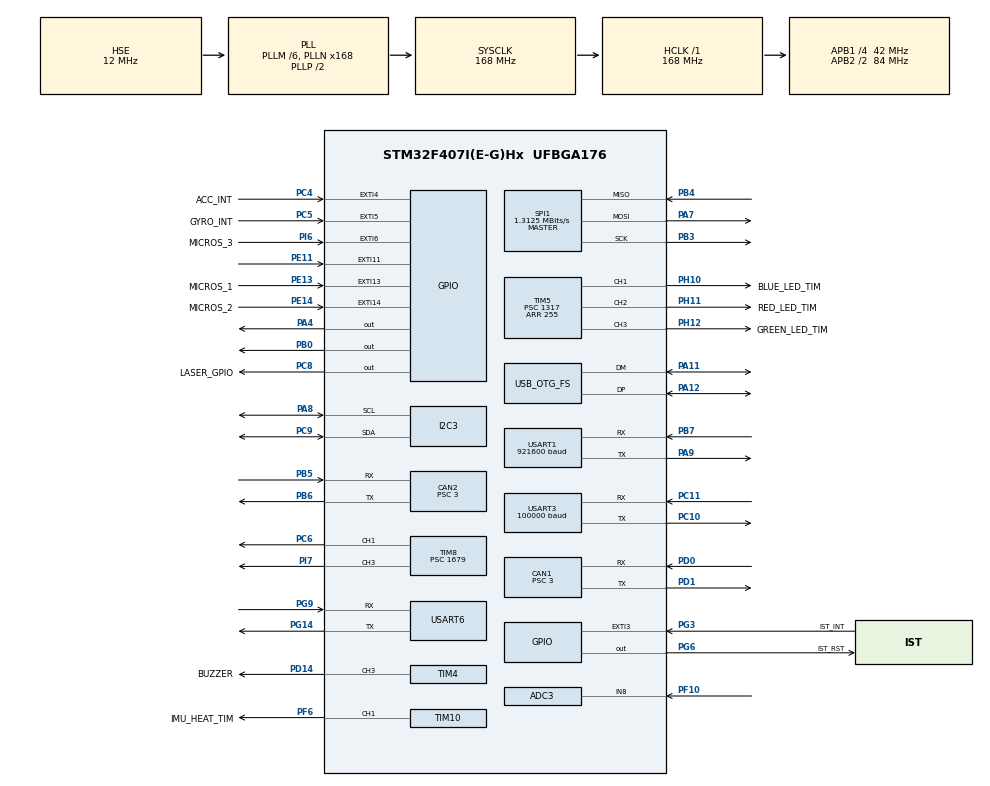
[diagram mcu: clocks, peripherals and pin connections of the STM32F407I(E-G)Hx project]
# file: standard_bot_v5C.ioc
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ADC3.Channel-0\#ChannelRegularConversion=ADC_CHANNEL_8
ADC3.NbrOfConversionFlag=1
ADC3.Rank-0\#ChannelRegularConversion=1
ADC3.SamplingTime-0\#ChannelRegularConversion=ADC_SAMPLETIME_3CYCLES
CAN1.ABOM=ENABLE
CAN1.BS1=CAN_BS1_10TQ
CAN1.BS2=CAN_BS2_3TQ
CAN1.CalculateBaudRate=1000000
CAN1.CalculateTimeBit=1000
CAN1.CalculateTimeQuantum=71.42857142857143
CAN1.NART=ENABLE
CAN1.Prescaler=3
CAN2.ABOM=ENABLE
CAN2.BS1=CAN_BS1_10TQ
CAN2.BS2=CAN_BS2_3TQ
CAN2.CalculateBaudRate=1000000
CAN2.CalculateTimeBit=1000
CAN2.CalculateTimeQuantum=71.42857142857143
CAN2.NART=ENABLE
CAN2.Prescaler=3
Dma.I2C3_RX.3.Direction=DMA_PERIPH_TO_MEMORY
Dma.I2C3_RX.3.FIFOMode=DMA_FIFOMODE_DISABLE
Dma.I2C3_RX.3.Instance=DMA1_Stream2
Dma.I2C3_RX.3.MemDataAlignment=DMA_MDATAALIGN_BYTE
Dma.I2C3_RX.3.MemInc=DMA_MINC_ENABLE
Dma.I2C3_RX.3.Mode=DMA_NORMAL
Dma.I2C3_RX.3.PeriphDataAlignment=DMA_PDATAALIGN_BYTE
Dma.I2C3_RX.3.PeriphInc=DMA_PINC_DISABLE
Dma.I2C3_RX.3.Priority=DMA_PRIORITY_LOW
Dma.I2C3_TX.4.Direction=DMA_MEMORY_TO_PERIPH
Dma.I2C3_TX.4.FIFOMode=DMA_FIFOMODE_DISABLE
Dma.I2C3_TX.4.Instance=DMA1_Stream4
Dma.I2C3_TX.4.MemDataAlignment=DMA_MDATAALIGN_BYTE
Dma.I2C3_TX.4.MemInc=DMA_MINC_ENABLE
Dma.I2C3_TX.4.Mode=DMA_NORMAL
Dma.I2C3_TX.4.PeriphDataAlignment=DMA_PDATAALIGN_BYTE
Dma.I2C3_TX.4.PeriphInc=DMA_PINC_DISABLE
Dma.I2C3_TX.4.Priority=DMA_PRIORITY_LOW
Dma.Request0=USART6_RX
Dma.Request1=USART3_RX
Dma.Request2=USART1_RX
Dma.Request3=I2C3_RX
Dma.Request4=I2C3_TX
Dma.Request5=SPI1_RX
Dma.Request6=SPI1_TX
Dma.Request7=USART6_TX
Dma.SPI1_RX.5.Direction=DMA_PERIPH_TO_MEMORY
Dma.SPI1_RX.5.FIFOMode=DMA_FIFOMODE_DISABLE
Dma.SPI1_RX.5.Instance=DMA2_Stream0
Dma.SPI1_RX.5.MemDataAlignment=DMA_MDATAALIGN_BYTE
Dma.SPI1_RX.5.MemInc=DMA_MINC_ENABLE
Dma.SPI1_RX.5.Mode=DMA_NORMAL
Dma.SPI1_RX.5.PeriphDataAlignment=DMA_PDATAALIGN_BYTE
Dma.SPI1_RX.5.PeriphInc=DMA_PINC_DISABLE
Dma.SPI1_RX.5.Priority=DMA_PRIORITY_LOW
Dma.SPI1_TX.6.Direction=DMA_MEMORY_TO_PERIPH
Dma.SPI1_TX.6.FIFOMode=DMA_FIFOMODE_DISABLE
Dma.SPI1_TX.6.Instance=DMA2_Stream3
Dma.SPI1_TX.6.MemDataAlignment=DMA_MDATAALIGN_BYTE
Dma.SPI1_TX.6.MemInc=DMA_MINC_ENABLE
Dma.SPI1_TX.6.Mode=DMA_NORMAL
Dma.SPI1_TX.6.PeriphDataAlignment=DMA_PDATAALIGN_BYTE
Dma.SPI1_TX.6.PeriphInc=DMA_PINC_DISABLE
Dma.SPI1_TX.6.Priority=DMA_PRIORITY_LOW
Dma.USART1_RX.2.Direction=DMA_PERIPH_TO_MEMORY
Dma.USART1_RX.2.FIFOMode=DMA_FIFOMODE_DISABLE
Dma.USART1_RX.2.Instance=DMA2_Stream5
Dma.USART1_RX.2.MemDataAlignment=DMA_MDATAALIGN_BYTE
Dma.USART1_RX.2.MemInc=DMA_MINC_ENABLE
Dma.USART1_RX.2.Mode=DMA_CIRCULAR
Dma.USART1_RX.2.PeriphDataAlignment=DMA_PDATAALIGN_BYTE
Dma.USART1_RX.2.PeriphInc=DMA_PINC_DISABLE
Dma.USART1_RX.2.Priority=DMA_PRIORITY_LOW
Dma.USART3_RX.1.Direction=DMA_PERIPH_TO_MEMORY
Dma.USART3_RX.1.FIFOMode=DMA_FIFOMODE_DISABLE
Dma.USART3_RX.1.Instance=DMA1_Stream1
Dma.USART3_RX.1.MemDataAlignment=DMA_MDATAALIGN_BYTE
Dma.USART3_RX.1.MemInc=DMA_MINC_ENABLE
Dma.USART3_RX.1.Mode=DMA_CIRCULAR
Dma.USART3_RX.1.PeriphDataAlignment=DMA_PDATAALIGN_BYTE
Dma.USART3_RX.1.PeriphInc=DMA_PINC_DISABLE
Dma.USART3_RX.1.Priority=DMA_PRIORITY_LOW
Dma.USART6_RX.0.Direction=DMA_PERIPH_TO_MEMORY
Dma.USART6_RX.0.FIFOMode=DMA_FIFOMODE_DISABLE
Dma.USART6_RX.0.Instance=DMA2_Stream1
Dma.USART6_RX.0.MemDataAlignment=DMA_MDATAALIGN_BYTE
Dma.USART6_RX.0.MemInc=DMA_MINC_ENABLE
Dma.USART6_RX.0.Mode=DMA_CIRCULAR
Dma.USART6_RX.0.PeriphDataAlignment=DMA_PDATAALIGN_BYTE
Dma.USART6_RX.0.PeriphInc=DMA_PINC_DISABLE
Dma.USART6_RX.0.Priority=DMA_PRIORITY_LOW
Dma.USART6_TX.7.Direction=DMA_MEMORY_TO_PERIPH
Dma.USART6_TX.7.FIFOMode=DMA_FIFOMODE_DISABLE
Dma.USART6_TX.7.Instance=DMA2_Stream6
Dma.USART6_TX.7.MemDataAlignment=DMA_MDATAALIGN_BYTE
Dma.USART6_TX.7.MemInc=DMA_MINC_ENABLE
Dma.USART6_TX.7.Mode=DMA_NORMAL
Dma.USART6_TX.7.PeriphDataAlignment=DMA_PDATAALIGN_BYTE
Dma.USART6_TX.7.PeriphInc=DMA_PINC_DISABLE
Dma.USART6_TX.7.Priority=DMA_PRIORITY_LOW
FREERTOS.INCLUDE_xEventGroupSetBitFromISR=1
FREERTOS.Tasks01=defaultTask,24,256,StartDefaultTask,Default,NULL,Dynamic,NULL,NULL
FREERTOS.configCHECK_FOR_STACK_OVERFLOW=1
FREERTOS.configENABLE_FPU=1
FREERTOS.configGENERATE_RUN_TIME_STATS=1
FREERTOS.configMINIMAL_STACK_SIZE=256
FREERTOS.configTOTAL_HEAP_SIZE=45000
FREERTOS.configUSE_NEWLIB_REENTRANT=1
FREERTOS.configUSE_STATS_FORMATTING_FUNCTIONS=1
I2C3.I2C_Mode=I2C_Fast
Mcu.Family=STM32F4
Mcu.Name=STM32F407I(E-G)Hx
Mcu.Package=UFBGA176
Mcu.UserConstants=FREERTOS_ENABLED,1
NVIC.CAN1_RX0_IRQn=true\:5\:0\:false\:false\:true\:true\:true\:true\:true
NVIC.CAN1_RX1_IRQn=true\:5\:0\:false\:false\:true\:true\:true\:true\:true
NVIC.CAN2_RX0_IRQn=true\:5\:0\:false\:false\:true\:true\:true\:true\:true
NVIC.CAN2_RX1_IRQn=true\:5\:0\:false\:false\:true\:true\:true\:true\:true
NVIC.DMA1_Stream1_IRQn=true\:5\:0\:false\:false\:true\:true\:false\:true\:true
NVIC.DMA1_Stream2_IRQn=true\:5\:0\:false\:false\:true\:true\:false\:true\:true
NVIC.DMA1_Stream4_IRQn=true\:5\:0\:false\:false\:true\:true\:false\:true\:true
NVIC.DMA2_Stream0_IRQn=true\:5\:0\:false\:false\:true\:true\:false\:true\:true
NVIC.DMA2_Stream1_IRQn=true\:5\:0\:false\:false\:true\:true\:false\:true\:true
NVIC.DMA2_Stream3_IRQn=true\:5\:0\:false\:false\:true\:true\:false\:true\:true
NVIC.DMA2_Stream5_IRQn=true\:5\:0\:false\:false\:true\:false\:false\:true\:true
NVIC.DMA2_Stream6_IRQn=true\:5\:0\:false\:false\:true\:true\:false\:true\:true
NVIC.EXTI15_10_IRQn=true\:5\:0\:false\:false\:true\:true\:true\:true\:true
NVIC.EXTI3_IRQn=true\:5\:0\:false\:false\:true\:true\:true\:true\:true
NVIC.EXTI4_IRQn=true\:5\:0\:false\:false\:true\:true\:true\:true\:true
NVIC.EXTI9_5_IRQn=true\:5\:0\:false\:false\:true\:true\:true\:true\:true
NVIC.I2C3_ER_IRQn=true\:5\:0\:false\:false\:true\:true\:true\:true\:true
NVIC.OTG_FS_IRQn=true\:5\:0\:false\:false\:true\:true\:false\:true\:true
NVIC.PriorityGroup=NVIC_PRIORITYGROUP_4
NVIC.TIM3_IRQn=true\:5\:0\:false\:false\:true\:true\:true\:true\:true
NVIC.TIM6_DAC_IRQn=true\:15\:0\:true\:false\:true\:false\:false\:true\:true
NVIC.TimeBase=TIM6_DAC_IRQn
NVIC.TimeBaseIP=TIM6
NVIC.USART1_IRQn=true\:5\:0\:false\:false\:true\:true\:true\:true\:true
NVIC.USART3_IRQn=true\:5\:0\:false\:false\:true\:true\:true\:true\:true
NVIC.USART6_IRQn=true\:5\:0\:false\:false\:true\:true\:true\:true\:true
PA11.Mode=Device_Only
PA11.Signal=USB_OTG_FS_DM
PA12.Mode=Device_Only
PA12.Signal=USB_OTG_FS_DP
PA13.Mode=Serial_Wire
PA13.Signal=SYS_JTMS-SWDIO
PA14.Mode=Serial_Wire
PA14.Signal=SYS_JTCK-SWCLK
PA4.PinState=GPIO_PIN_SET
PA4.Signal=GPIO_Output
PA7.Mode=Full_Duplex_Master
PA7.Signal=SPI1_MOSI
PA8.GPIO_Pu=GPIO_PULLUP
PA8.Mode=I2C
PA8.Signal=I2C3_SCL
PA9.Mode=Asynchronous
PA9.Signal=USART1_TX
PB0.PinState=GPIO_PIN_SET
PB0.Signal=GPIO_Output
PB3.Mode=Full_Duplex_Master
PB3.Signal=SPI1_SCK
PB4.Mode=Full_Duplex_Master
PB4.Signal=SPI1_MISO
PB5.Mode=CAN_Activate
PB5.Signal=CAN2_RX
PB6.Mode=CAN_Activate
PB6.Signal=CAN2_TX
PB7.GPIO_PuPd=GPIO_NOPULL
PB7.Mode=Asynchronous
PB7.Signal=USART1_RX
PC10.Mode=Asynchronous
PC10.Signal=USART3_TX
PC11.Mode=Asynchronous
PC11.Signal=USART3_RX
PC4.GPIO_Label=ACC_INT
PC4.GPIO_ModeDefaultEXTI=GPIO_MODE_IT_FALLING
PC4.GPIO_PuPd=GPIO_PULLUP
PC4.Signal=GPXTI4
PC5.GPIO_Label=GYRO_INT
PC5.GPIO_ModeDefaultEXTI=GPIO_MODE_IT_FALLING
PC5.GPIO_PuPd=GPIO_PULLUP
PC5.Signal=GPXTI5
PC6.Signal=S_TIM8_CH1
PC8.GPIO_Label=LASER_GPIO
PC8.PinState=GPIO_PIN_RESET
PC8.Signal=GPIO_Output
PC9.GPIO_Pu=GPIO_PULLUP
PC9.Mode=I2C
PC9.Signal=I2C3_SDA
PD0.Mode=CAN_Activate
PD0.Signal=CAN1_RX
PD1.Mode=CAN_Activate
PD1.Signal=CAN1_TX
PD14.GPIO_Label=BUZZER
PD14.Signal=S_TIM4_CH3
PE11.GPIO_ModeDefaultEXTI=GPIO_MODE_IT_RISING_FALLING
PE11.GPIO_PuPd=GPIO_PULLDOWN
PE11.Signal=GPXTI11
PE13.GPIO_Label=MICROS_1
PE13.GPIO_ModeDefaultEXTI=GPIO_MODE_IT_RISING_FALLING
PE13.GPIO_PuPd=GPIO_PULLUP
PE13.Signal=GPXTI13
PE14.GPIO_Label=MICROS_2
PE14.GPIO_PuPd=GPIO_PULLUP
PE14.Signal=GPXTI14
PF10.Mode=IN8
PF10.Signal=ADC3_IN8
PF6.GPIO_Label=IMU_HEAT_TIM
PF6.Signal=S_TIM10_CH1
PG14.Mode=Asynchronous
PG14.Signal=USART6_TX
PG3.GPIO_Label=IST_INT
PG3.GPIO_ModeDefaultEXTI=GPIO_MODE_IT_FALLING
PG3.GPIO_PuPd=GPIO_PULLUP
PG3.Signal=GPXTI3
PG6.GPIO_Label=IST_RST
PG6.Signal=GPIO_Output
PG9.Mode=Asynchronous
PG9.Signal=USART6_RX
PH0-OSC_IN.Mode=HSE-External-Oscillator
PH0-OSC_IN.Signal=RCC_OSC_IN
PH1-OSC_OUT.Mode=HSE-External-Oscillator
PH1-OSC_OUT.Signal=RCC_OSC_OUT
PH10.GPIO_Label=BLUE_LED_TIM
PH10.Signal=S_TIM5_CH1
PH11.GPIO_Label=RED_LED_TIM
PH11.Signal=S_TIM5_CH2
PH12.GPIO_Label=GREEN_LED_TIM
PH12.Signal=S_TIM5_CH3
PI6.GPIO_Label=MICROS_3
PI6.GPIO_PuPd=GPIO_PULLUP
PI6.Signal=GPXTI6
PI7.Signal=S_TIM8_CH3
ProjectManager.HeapSize=0x4000
ProjectManager.StackSize=0x9000
ProjectManager.TargetToolchain=STM32CubeIDE
RCC.48MHZClocksFreq_Value=48000000
RCC.AHBFreq_Value=168000000
RCC.APB1CLKDivider=RCC_HCLK_DIV4
RCC.APB1Freq_Value=42000000
RCC.APB1TimFreq_Value=84000000
RCC.APB2CLKDivider=RCC_HCLK_DIV2
RCC.APB2Freq_Value=84000000
RCC.APB2TimFreq_Value=168000000
RCC.CortexFreq_Value=168000000
RCC.HCLKFreq_Value=168000000
RCC.HSE_VALUE=12000000
RCC.HSI_VALUE=16000000
RCC.LSE_VALUE=32768
RCC.PLLM=6
RCC.PLLN=168
RCC.PLLQ=7
RCC.SYSCLKFreq_VALUE=168000000
RCC.SYSCLKSource=RCC_SYSCLKSOURCE_PLLCLK
RCC.VCOOutputFreq_Value=336000000
SH.S_TIM10_CH1.0=TIM10_CH1,PWM Generation1 CH1
SH.S_TIM4_CH3.0=TIM4_CH3,PWM Generation3 CH3
SH.S_TIM5_CH1.0=TIM5_CH1,PWM Generation1 CH1
SH.S_TIM5_CH2.0=TIM5_CH2,PWM Generation2 CH2
SH.S_TIM5_CH3.0=TIM5_CH3,PWM Generation3 CH3
SH.S_TIM8_CH1.0=TIM8_CH1,PWM Generation1 CH1
SH.S_TIM8_CH3.0=TIM8_CH3,PWM Generation3 CH3
SPI1.BaudRatePrescaler=SPI_BAUDRATEPRESCALER_64
SPI1.CalculateBaudRate=1.3125 MBits/s
SPI1.Direction=SPI_DIRECTION_2LINES
SPI1.Mode=SPI_MODE_MASTER
SPI1.VirtualType=VM_MASTER
TIM10.Channel=TIM_CHANNEL_1
TIM3.Channel-Output\ Compare1\ No\ Output=TIM_CHANNEL_1
TIM3.Period=1
TIM3.Prescaler=168-1
TIM4.Channel-PWM\ Generation3\ CH3=TIM_CHANNEL_3
TIM4.Period=1000-1
TIM4.Prescaler=1000-1
TIM5.AutoReloadPreload=TIM_AUTORELOAD_PRELOAD_ENABLE
TIM5.Channel-PWM\ Generation1\ CH1=TIM_CHANNEL_1
TIM5.Channel-PWM\ Generation2\ CH2=TIM_CHANNEL_2
TIM5.Channel-PWM\ Generation3\ CH3=TIM_CHANNEL_3
TIM5.OCFastMode_PWM-PWM\ Generation1\ CH1=TIM_OCFAST_ENABLE
TIM5.OCFastMode_PWM-PWM\ Generation2\ CH2=TIM_OCFAST_ENABLE
TIM5.OCFastMode_PWM-PWM\ Generation3\ CH3=TIM_OCFAST_ENABLE
TIM5.OCMode_PWM-PWM\ Generation2\ CH2=TIM_OCMODE_PWM1
TIM5.OCPolarity_1=TIM_OCPOLARITY_LOW
TIM5.OCPolarity_2=TIM_OCPOLARITY_LOW
TIM5.OCPolarity_3=TIM_OCPOLARITY_LOW
TIM5.Period=255
TIM5.Prescaler=1317
TIM8.Channel-PWM\ Generation1\ CH1=TIM_CHANNEL_1
TIM8.Channel-PWM\ Generation3\ CH3=TIM_CHANNEL_3
TIM8.Period=1999
TIM8.Prescaler=1679
USART1.BaudRate=921600
USART1.Mode=MODE_TX_RX
USART1.VirtualMode=VM_ASYNC
USART3.BaudRate=100000
USART3.Parity=PARITY_EVEN
USART3.VirtualMode=VM_ASYNC
USART3.WordLength=WORDLENGTH_9B
USART6.VirtualMode=VM_ASYNC
USB_DEVICE.CLASS_NAME_FS=CDC
USB_DEVICE.VirtualMode-CDC_FS=Cdc
USB_DEVICE.VirtualModeFS=Cdc_FS
USB_OTG_FS.VirtualMode=Device_Only
VP_CRC_VS_CRC.Mode=CRC_Activate
VP_FREERTOS_VS_CMSIS_V2.Mode=CMSIS_V2
VP_RNG_VS_RNG.Mode=RNG_Activate
VP_SYS_VS_tim6.Mode=TIM6
VP_TIM10_VS_ClockSourceINT.Mode=Enable_Timer
VP_TIM2_VS_ClockSourceINT.Mode=Internal
VP_TIM3_VS_ClockSourceINT.Mode=Internal
VP_TIM3_VS_no_output1.Mode=Output Compare1 No Output
VP_USB_DEVICE_VS_USB_DEVICE_CDC_FS.Mode=CDC_FS
board=custom

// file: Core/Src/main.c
/* USER CODE BEGIN Header */
/**
  ******************************************************************************
  * @file           : main.c
  * @brief          : Main program body
  ******************************************************************************
  * @attention
  *
  * Copyright (c) 2025 STMicroelectronics.
  * All rights reserved.
  *
  * This software is licensed under terms that can be found in the LICENSE file
  * in the root directory of this software component.
  * If no LICENSE file comes with this software, it is provided AS-IS.
  *
  ******************************************************************************
  */
/* USER CODE END Header */
#include "main.h"
#include "cmsis_os.h"
#include "adc.h"
#include "can.h"
#include "crc.h"
#include "dma.h"
#include "i2c.h"
#include "rng.h"
#include "spi.h"
#include "tim.h"
#include "usart.h"
#include "usb_device.h"
#include "gpio.h"

/* USER CODE BEGIN Includes */
#include "board_lib.h"

#include "startup.h"
/* USER CODE END Includes */

void SystemClock_Config(void);
void MX_FREERTOS_Init(void);

int main(void)
{

  /* MCU Configuration--------------------------------------------------------*/

  /* Reset of all peripherals, Initializes the Flash interface and the Systick. */
  HAL_Init();

  /* Configure the system clock */
  SystemClock_Config();

  /* Initialize all configured peripherals */
  MX_GPIO_Init();
  MX_DMA_Init();
  MX_CAN1_Init();
  MX_CAN2_Init();
  MX_TIM5_Init();
  MX_TIM10_Init();
  MX_USART1_UART_Init();
  MX_USART3_UART_Init();
  MX_USART6_UART_Init();
  MX_SPI1_Init();
  MX_I2C3_Init();
  MX_ADC3_Init();
  MX_TIM3_Init();
  MX_TIM4_Init();
  MX_RNG_Init();
  MX_TIM2_Init();
  MX_CRC_Init();
  MX_TIM8_Init();
  /* USER CODE BEGIN 2 */
//  MX_USB_DEVICE_Init();
  HAL_TIM_Base_Start(&htim3); //start micros clock
//  NVIC_SetPriority(SysTick_IRQn, 15);
//  HAL_RNG_GenerateRandomNumber(hrng, random32bit)
  /* USER CODE END 2 */

  /* Init scheduler */
  osKernelInitialize();  /* Call init function for freertos objects (in cmsis_os2.c) */
  MX_FREERTOS_Init();

  /* Start scheduler */
  osKernelStart();

  /* We should never get here as control is now taken by the scheduler */

  /* Infinite loop */
  while (1)
  {

  }
}

void SystemClock_Config(void)
{
  RCC_OscInitTypeDef RCC_OscInitStruct = {0};
  RCC_ClkInitTypeDef RCC_ClkInitStruct = {0};

  /** Configure the main internal regulator output voltage
  */
  __HAL_RCC_PWR_CLK_ENABLE();
  __HAL_PWR_VOLTAGESCALING_CONFIG(PWR_REGULATOR_VOLTAGE_SCALE1);

  /** Initializes the RCC Oscillators according to the specified parameters
  * in the RCC_OscInitTypeDef structure.
  */
  RCC_OscInitStruct.OscillatorType = RCC_OSCILLATORTYPE_HSE;
  RCC_OscInitStruct.HSEState = RCC_HSE_ON;
  RCC_OscInitStruct.PLL.PLLState = RCC_PLL_ON;
  RCC_OscInitStruct.PLL.PLLSource = RCC_PLLSOURCE_HSE;
  RCC_OscInitStruct.PLL.PLLM = 6;
  RCC_OscInitStruct.PLL.PLLN = 168;
  RCC_OscInitStruct.PLL.PLLP = RCC_PLLP_DIV2;
  RCC_OscInitStruct.PLL.PLLQ = 7;
  if (HAL_RCC_OscConfig(&RCC_OscInitStruct) != HAL_OK)
  {
    Error_Handler();
  }

  /** Initializes the CPU, AHB and APB buses clocks
  */
  RCC_ClkInitStruct.ClockType = RCC_CLOCKTYPE_HCLK|RCC_CLOCKTYPE_SYSCLK
                              |RCC_CLOCKTYPE_PCLK1|RCC_CLOCKTYPE_PCLK2;
  RCC_ClkInitStruct.SYSCLKSource = RCC_SYSCLKSOURCE_PLLCLK;
  RCC_ClkInitStruct.AHBCLKDivider = RCC_SYSCLK_DIV1;
  RCC_ClkInitStruct.APB1CLKDivider = RCC_HCLK_DIV4;
  RCC_ClkInitStruct.APB2CLKDivider = RCC_HCLK_DIV2;

  if (HAL_RCC_ClockConfig(&RCC_ClkInitStruct, FLASH_LATENCY_5) != HAL_OK)
  {
    Error_Handler();
  }
}

void HAL_TIM_PeriodElapsedCallback(TIM_HandleTypeDef *htim)
{
  if (htim->Instance == TIM6)
  {
    HAL_IncTick();
  }
}

void Error_Handler(void)
{
  __disable_irq();
  while (1)
  {
  }
}

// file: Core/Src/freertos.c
/* USER CODE BEGIN Header */
/**
  ******************************************************************************
  * File Name          : freertos.c
  * Description        : Code for freertos applications
  ******************************************************************************
  * @attention
  *
  * Copyright (c) 2025 STMicroelectronics.
  * All rights reserved.
  *
  * This software is licensed under terms that can be found in the LICENSE file
  * in the root directory of this software component.
  * If no LICENSE file comes with this software, it is provided AS-IS.
  *
  ******************************************************************************
  */
/* USER CODE END Header */

#include "FreeRTOS.h"
#include "task.h"
#include "main.h"
#include "cmsis_os.h"

/* USER CODE BEGIN Includes */
#include "can.h"
#include "stdint.h"
#include "master_task.h"

/* USER CODE END Includes */

/* USER CODE BEGIN PD */
//FreeRTOS definitions
#define ISR_SEMAPHORE_COUNT 1
#define QUEUE_SIZE 1

/* USER CODE END PD */

/* USER CODE BEGIN Variables */
TaskHandle_t master_task_handle;

/* USER CODE END Variables */
/* Definitions for defaultTask */
osThreadId_t defaultTaskHandle;
const osThreadAttr_t defaultTask_attributes = {
  .name = "defaultTask",
  .stack_size = 256 * 4,
  .priority = (osPriority_t) osPriorityNormal,
};

void StartDefaultTask(void *argument);

extern void MX_USB_DEVICE_Init(void);
void MX_FREERTOS_Init(void); /* (MISRA C 2004 rule 8.1) */

/* Hook prototypes */
void configureTimerForRunTimeStats(void);
unsigned long getRunTimeCounterValue(void);
void vApplicationStackOverflowHook(xTaskHandle xTask, signed char *pcTaskName);

/* USER CODE BEGIN 1 */
/* Functions needed when configGENERATE_RUN_TIME_STATS is on */
__weak void configureTimerForRunTimeStats(void)
{

}

__weak unsigned long getRunTimeCounterValue(void)
{
return 0;
}
/* USER CODE END 1 */

/* USER CODE BEGIN 4 */
void vApplicationStackOverflowHook(xTaskHandle xTask, signed char *pcTaskName)
{
   /* Run time stack overflow checking is performed if
   configCHECK_FOR_STACK_OVERFLOW is defined to 1 or 2. This hook function is
   called if a stack overflow is detected. */
}
/* USER CODE END 4 */

void MX_FREERTOS_Init(void) {

  /* Create the thread(s) */
  /* creation of defaultTask */
  defaultTaskHandle = osThreadNew(StartDefaultTask, NULL, &defaultTask_attributes);

  /* USER CODE BEGIN RTOS_THREADS */
  /* add threads, ... */
//  telemetry_setup_wrapper();
  xTaskCreate(master_task, "master_task", configMINIMAL_STACK_SIZE,
		  (void*) 1, (UBaseType_t) 12, &master_task_handle);
  /* USER CODE END RTOS_THREADS */

}

void StartDefaultTask(void *argument)
{
  /* init code for USB_DEVICE */
  MX_USB_DEVICE_Init();
  /* USER CODE BEGIN StartDefaultTask */
  // Terminate task immediately
  osThreadId_t currTask = osThreadGetId();
  osThreadTerminate(currTask);
  /* Infinite loop */
  for(;;)
  {
    osDelay(1);
  }
  /* USER CODE END StartDefaultTask */
}
